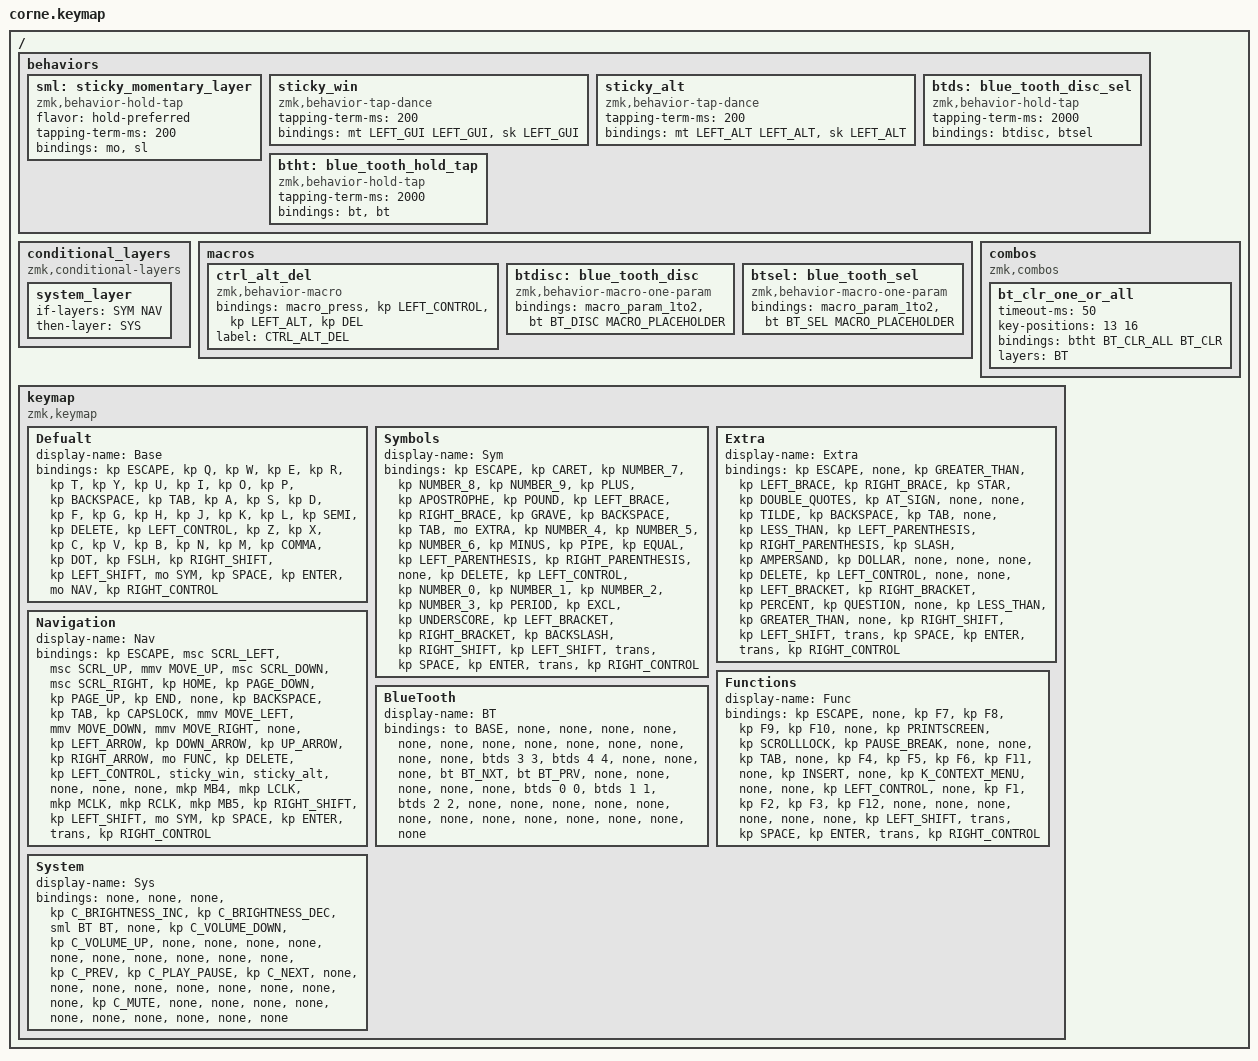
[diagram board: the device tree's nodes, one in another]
#include <behaviors.dtsi>
#include <dt-bindings/zmk/bt.h>
#include <dt-bindings/zmk/keys.h>
#include <dt-bindings/zmk/pointing.h>

#define BASE 0
#define SYM 1
#define EXTRA 2
#define NAV 3
#define FUNC 4
#define SYS 5
#define BT 6

//  +----+----+----+----+----+----+                +----+----+----+----+----+----+
//  |  0 |  1 |  2 |  3 |  4 |  5 |                |  6 |  7 |  8 |  9 | 10 | 11 |
//  +----+----+----+----+----+----+                +----+----+----+----+----+----+
//  | 12 | 13 | 14 | 15 | 16 | 17 |                | 18 | 19 | 20 | 21 | 22 | 23 |
//  +----+----+----+----+----+----+                +----+----+----+----+----+----+
//  | 14 | 25 | 26 | 27 | 28 | 29 |                | 30 | 31 | 32 | 33 | 34 | 35 |
//  +----+----+----+----+----+----++----+    +----++----+----+----+----+----+----+
//                     +----++----+|    |    |    |+----++----+
//                     | 36 || 37 || 38 |    | 39 || 40 || 41 |
//                     +----++----++----+    +----++----++----+


/ {
    behaviors {
        sml: sticky_momentary_layer {
            compatible = "zmk,behavior-hold-tap";
            #binding-cells = <2>;
            flavor = "hold-preferred";
            tapping-term-ms = <200>;
            bindings = <&mo>, <&sl>;
        };

        sticky_win: sticky_win {
            compatible = "zmk,behavior-tap-dance";
            #binding-cells = <0>;
            tapping-term-ms = <200>;
            bindings = <&mt LEFT_GUI LEFT_GUI>, <&sk LEFT_GUI>;
        };

        sticky_alt: sticky_alt {
            compatible = "zmk,behavior-tap-dance";
            #binding-cells = <0>;
            tapping-term-ms = <200>;
            bindings = <&mt LEFT_ALT LEFT_ALT>, <&sk LEFT_ALT>;
        };

        btds: blue_tooth_disc_sel {
            compatible = "zmk,behavior-hold-tap";
            #binding-cells = <2>; 
            tapping-term-ms = <2000>;
            bindings = <&btdisc>, <&btsel>;
        };

        btht: blue_tooth_hold_tap {
            compatible = "zmk,behavior-hold-tap";
            #binding-cells = <2>;
            tapping-term-ms = <2000>;
            bindings = <&bt>, <&bt>;
        };
    };

    conditional_layers {
        compatible = "zmk,conditional-layers";
        system_layer {
            if-layers = <SYM NAV>;
            then-layer = <SYS>;
        };
    };

    macros {
        ctrl_alt_del: ctrl_alt_del {
            compatible = "zmk,behavior-macro";
            #binding-cells = <0>;
            bindings = <&macro_press>, <&kp LEFT_CONTROL &kp LEFT_ALT &kp DEL>;

            label = "CTRL_ALT_DEL";
        };

        btdisc: blue_tooth_disc {
            compatible = "zmk,behavior-macro-one-param";
            #binding-cells = <1>;
            bindings
                = <&macro_param_1to2>
                , <&bt BT_DISC MACRO_PLACEHOLDER>;
        };

        btsel: blue_tooth_sel {
            compatible = "zmk,behavior-macro-one-param";
            #binding-cells = <1>;
            bindings
                = <&macro_param_1to2>
                , <&bt BT_SEL MACRO_PLACEHOLDER>;
        };
    };

    combos {
        compatible = "zmk,combos";

        bt_clr_one_or_all {
            timeout-ms = <50>;
            key-positions = <13 16>;
            bindings = <&btht BT_CLR_ALL BT_CLR>;
            layers = <BT>;
        };
    };

    keymap {
        compatible = "zmk,keymap";

        Defualt {
            display-name = "Base";

//  +----+----+----+----+----+----+                +----+----+----+----+----+----+
//  |Esc |  q |  w |  e |  r |  t |                |  y |  u |  i |  o |  p |Bksp|
//  +----+----+----+----+----+----+                +----+----+----+----+----+----+
//  |Tab |  a |  s |  d |  f |  g |                |  h |  j |  k |  l |  ; |Del |
//  +----+----+----+----+----+----+                +----+----+----+----+----+----+
//  | LC |  z |  x |  c |  v |  b |                |  n |  m |  , |  . |  / | RS |
//  +----+----+----+----+----+----++----+    +----++----+----+----+----+----+----+
//                     +----++----+|    |    |    |+----++----+
//                     | LS ||Sym ||Spc |    |Entr||Nav || RC |
//                     +----++----++----+    +----++----++----+

            bindings = <
                &kp ESCAPE
                &kp Q
                &kp W
                &kp E
                &kp R
                &kp T

                &kp Y
                &kp U
                &kp I
                &kp O
                &kp P
                &kp BACKSPACE


                &kp TAB
                &kp A
                &kp S
                &kp D
                &kp F
                &kp G

                &kp H
                &kp J
                &kp K
                &kp L
                &kp SEMI
                &kp DELETE


                &kp LEFT_CONTROL
                &kp Z
                &kp X
                &kp C
                &kp V
                &kp B

                &kp N
                &kp M
                &kp COMMA
                &kp DOT
                &kp FSLH
                &kp RIGHT_SHIFT


                &kp LEFT_SHIFT
                &mo SYM
                &kp SPACE

                &kp ENTER
                &mo NAV
                &kp RIGHT_CONTROL

            >;
        };

        Symbols {
            display-name = "Sym";

//  +----+----+----+----+----+----+                +----+----+----+----+----+----+
//  |Esc |  ^ |  7 |  8 |  9 |  + |                |  ' |  # |  { |  } |  ` |Bksp|
//  +----+----+----+----+----+----+                +----+----+----+----+----+----+
//  |Tab |Extr|  4 |  5 |  6 |  - |                |  | |  = |  ( |  ) |    |Del |
//  +----+----+----+----+----+----+                +----+----+----+----+----+----+
//  | LC |  0 |  1 |  2 |  3 |  . |                |  ! |  _ |  [ |  ] |  \ | RS |
//  +----+----+----+----+----+----++----+    +----++----+----+----+----+----+----+
//                     +----++----+|    |    |    |+----++----+
//                     | LS || ** ||Spc |    |Entr||Sys || RC |
//                     +----++----++----+    +----++----++----+

            bindings = <
                &kp ESCAPE
                &kp CARET
                &kp NUMBER_7
                &kp NUMBER_8
                &kp NUMBER_9
                &kp PLUS

                &kp APOSTROPHE
                &kp POUND
                &kp LEFT_BRACE
                &kp RIGHT_BRACE
                &kp GRAVE
                &kp BACKSPACE


                &kp TAB
                &mo EXTRA
                &kp NUMBER_4
                &kp NUMBER_5
                &kp NUMBER_6
                &kp MINUS

                &kp PIPE
                &kp EQUAL
                &kp LEFT_PARENTHESIS
                &kp RIGHT_PARENTHESIS
                &none
                &kp DELETE


                &kp LEFT_CONTROL
                &kp NUMBER_0
                &kp NUMBER_1
                &kp NUMBER_2
                &kp NUMBER_3
                &kp PERIOD

                &kp EXCL
                &kp UNDERSCORE
                &kp LEFT_BRACKET
                &kp RIGHT_BRACKET
                &kp BACKSLASH
                &kp RIGHT_SHIFT


                &kp LEFT_SHIFT
                &trans
                &kp SPACE

                &kp ENTER
                &trans
                &kp RIGHT_CONTROL

            >;
        };


        Extra {
            display-name = "Extra";

//  +----+----+----+----+----+----+                +----+----+----+----+----+----+
//  |Esc |    |  > |  { |  } |  * |                |  " |  @ |    |    |  ~ |Bksp|
//  +----+----+----+----+----+----+                +----+----+----+----+----+----+
//  |Tab | ** |  < |  ( |  ) |  / |                |  & |  $ |    |    |    |Del |
//  +----+----+----+----+----+----+                +----+----+----+----+----+----+
//  | LC |    |    |  [ |  ] |  % |                |  ? |    |  < |  > |    | RS |
//  +----+----+----+----+----+----++----+    +----++----+----+----+----+----+----+
//                     +----++----+|    |    |    |+----++----+
//                     | LS || ** ||Spc |    |Entr||    || RC |
//                     +----++----++----+    +----++----++----+

            bindings = <
                &kp ESCAPE
                &none
                &kp GREATER_THAN
                &kp LEFT_BRACE
                &kp RIGHT_BRACE
                &kp STAR

                &kp DOUBLE_QUOTES
                &kp AT_SIGN
                &none
                &none
                &kp TILDE
                &kp BACKSPACE


                &kp TAB
                &none
                &kp LESS_THAN
                &kp LEFT_PARENTHESIS
                &kp RIGHT_PARENTHESIS
                &kp SLASH

                &kp AMPERSAND
                &kp DOLLAR
                &none
                &none
                &none
                &kp DELETE


                &kp LEFT_CONTROL
                &none
                &none
                &kp LEFT_BRACKET
                &kp RIGHT_BRACKET
                &kp PERCENT

                &kp QUESTION
                &none
                &kp LESS_THAN
                &kp GREATER_THAN
                &none
                &kp RIGHT_SHIFT


                &kp LEFT_SHIFT
                &trans
                &kp SPACE

                &kp ENTER
                &trans
                &kp RIGHT_CONTROL

            >;
        };

        Navigation {
            display-name = "Nav";

//  +----+----+----+----+----+----+                +----+----+----+----+----+----+
//  |Esc |Lsc |Usc |Mup |Dsc |Rsc |                |Home|PgDn|PgUp|End |    |Bksp|
//  +----+----+----+----+----+----+                +----+----+----+----+----+----+
//  |Tab |Caps| Ml |Mdn | Mr |    |                | <- | \/ | /\ | -> |Func|Del |
//  +----+----+----+----+----+----+                +----+----+----+----+----+----+
//  | LC |Win |Alt |    |    |    |                |MB4 |Lclk|Wclk|Rclk|MB5 | RS |
//  +----+----+----+----+----+----++----+    +----++----+----+----+----+----+----+
//                     +----++----+|    |    |    |+----++----+
//                     | LS ||Sys ||Spc |    |Entr|| ** || RC |
//                     +----++----++----+    +----++----++----+

            bindings = <
                &kp ESCAPE
                &msc SCRL_LEFT
                &msc SCRL_UP
                &mmv MOVE_UP
                &msc SCRL_DOWN
                &msc SCRL_RIGHT

                &kp HOME
                &kp PAGE_DOWN
                &kp PAGE_UP
                &kp END
                &none
                &kp BACKSPACE


                &kp TAB
                &kp CAPSLOCK
                &mmv MOVE_LEFT
                &mmv MOVE_DOWN
                &mmv MOVE_RIGHT
                &none

                &kp LEFT_ARROW
                &kp DOWN_ARROW
                &kp UP_ARROW
                &kp RIGHT_ARROW
                &mo FUNC
                &kp DELETE


                &kp LEFT_CONTROL
                &sticky_win
                &sticky_alt
                &none
                &none
                &none

                &mkp MB4
                &mkp LCLK
                &mkp MCLK
                &mkp RCLK
                &mkp MB5
                &kp RIGHT_SHIFT


                &kp LEFT_SHIFT
                &mo SYM
                &kp SPACE

                &kp ENTER
                &trans
                &kp RIGHT_CONTROL

            >;
        };

        Functions {
            display-name = "Func";

//  +----+----+----+----+----+----+                +----+----+----+----+----+----+
//  |Esc |    | F7 | F8 | F9 |F10 |                |    |PRSC|SCLK|PA/B|    |Bksp|
//  +----+----+----+----+----+----+                +----+----+----+----+----+----+
//  |Tab |    | F4 | F5 | F6 |F11 |                |    |Insr|    |MENU| ** |Del |
//  +----+----+----+----+----+----+                +----+----+----+----+----+----+
//  | LC |    | F1 | F2 | F3 |F12 |                |    |    |    |    |    | RS |
//  +----+----+----+----+----+----++----+    +----++----+----+----+----+----+----+
//                     +----++----+|    |    |    |+----++----+
//                     | LS ||Sys ||Spc |    |Entr|| ** || RC |
//                     +----++----++----+    +----++----++----+

            bindings = <
                &kp ESCAPE
                &none
                &kp F7
                &kp F8
                &kp F9
                &kp F10

                &none
                &kp PRINTSCREEN
                &kp SCROLLLOCK
                &kp PAUSE_BREAK
                &none
                &none


                &kp TAB
                &none
                &kp F4
                &kp F5
                &kp F6
                &kp F11

                &none
                &kp INSERT
                &none
                &kp K_CONTEXT_MENU
                &none
                &none


                &kp LEFT_CONTROL
                &none
                &kp F1
                &kp F2
                &kp F3
                &kp F12

                &none
                &none
                &none
                &none
                &none
                &none


                &kp LEFT_SHIFT
                &trans
                &kp SPACE

                &kp ENTER
                &trans
                &kp RIGHT_CONTROL

            >;
        };

        System {
            display-name = "Sys";

//  +----+----+----+----+----+----+                +----+----+----+----+----+----+
//  |    |    |    |BrUp|BrDn| BT |                |    |Vdn |Vup |    |    |    |
//  +----+----+----+----+----+----+                +----+----+----+----+----+----+
//  |    |    |    |    |    |    |                |    | << | PP | >> |    |    |
//  +----+----+----+----+----+----+                +----+----+----+----+----+----+
//  |    |    |    |    |    |    |                |    |MUTE|    |    |    |    |
//  +----+----+----+----+----+----++----+    +----++----+----+----+----+----+----+
//                     +----++----+|    |    |    |+----++----+
//                     |    || ** ||    |    |    || ** ||    |
//                     +----++----++----+    +----++----++----+

            bindings = <
                &none
                &none
                &none
                &kp C_BRIGHTNESS_INC
                &kp C_BRIGHTNESS_DEC
                &sml BT BT

                &none
                &kp C_VOLUME_DOWN
                &kp C_VOLUME_UP
                &none
                &none
                &none


                &none
                &none
                &none
                &none
                &none
                &none

                &none
                &kp C_PREV
                &kp C_PLAY_PAUSE
                &kp C_NEXT
                &none
                &none


                &none
                &none
                &none
                &none
                &none
                &none

                &none
                &kp C_MUTE
                &none
                &none
                &none
                &none


                &none
                &none
                &none

                &none
                &none
                &none

            >;
        };


        BlueTooth {
            display-name = "BT";

//  +----+----+----+----+----+----+                +----+----+----+----+----+----+
//  |Base|    |    |    |    | ** |                |    |    |    |    |    |    |
//  +----+----+----+----+----+----+                +----+----+----+----+----+----+
//  |    |BtCl|Bt4 |Bt5 |BtCl|    |                |    |Next|Prev|    |    |    |
//  +----+----+----+----+----+----+                +----+----+----+----+----+----+
//  |    |    |Bt1 |Bt2 |Bt3 |    |                |    |    |    |    |    |    |
//  +----+----+----+----+----+----++----+    +----++----+----+----+----+----+----+
//                     +----++----+|    |    |    |+----++----+
//                     |    ||    ||    |    |    ||    ||    |
//                     +----++----++----+    +----++----++----+

            bindings = <
                &to BASE
                &none
                &none
                &none
                &none
                &none

                &none
                &none
                &none
                &none
                &none
                &none


                &none
                &none
                &btds 3 3
                &btds 4 4
                &none
                &none

                &none
                &bt BT_NXT
                &bt BT_PRV
                &none
                &none
                &none


                &none
                &none
                &btds 0 0
                &btds 1 1
                &btds 2 2
                &none

                &none
                &none
                &none
                &none
                &none
                &none


                &none
                &none
                &none

                &none
                &none
                &none

            >;
        };
    };
};
